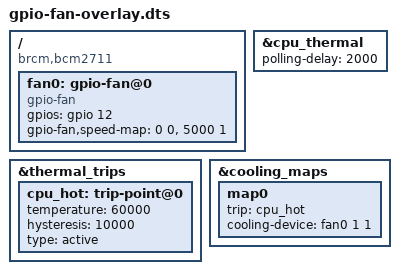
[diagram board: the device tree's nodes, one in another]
/* modified https://github.com/raspberrypi/linux/blob/fb6ce65000734ccf6d371b4f0e74716d14cc1972/arch/arm/boot/dts/overlays/gpio-fan-overlay.dts */
/dts-v1/;
/plugin/;

/ {
	compatible = "brcm,bcm2711";

	fragment@0 {
		target-path = "/";
		__overlay__ {
			fan0: gpio-fan@0 {
				compatible = "gpio-fan";
				gpios = <&gpio 12 0>;
				gpio-fan,speed-map = <0    0>,
									 <5000 1>;
				#cooling-cells = <2>;
			};
		};
	};

	fragment@1 {
		target = <&cpu_thermal>;
		__overlay__ {
			polling-delay = <2000>;	/* milliseconds */
		};
	};

	fragment@2 {
		target = <&thermal_trips>;
		__overlay__ {
			cpu_hot: trip-point@0 {
				temperature = <60000>;	/* (millicelsius) Fan started at 60°C */
				hysteresis = <10000>;	/* (millicelsius) Fan stopped at 50°C */
				type = "active";
			};
		};
	};

	fragment@3 {
		target = <&cooling_maps>;
		__overlay__ {
			map0 {
				trip = <&cpu_hot>;
				cooling-device = <&fan0 1 1>;
			};
		};
	};

	__overrides__ {
		gpiopin = <&fan0>,"gpios:4", <&fan0>,"brcm,pins:0";
		temp = <&cpu_hot>,"temperature:0";
		hyst = <&cpu_hot>,"hysteresis:0";
	};
};
